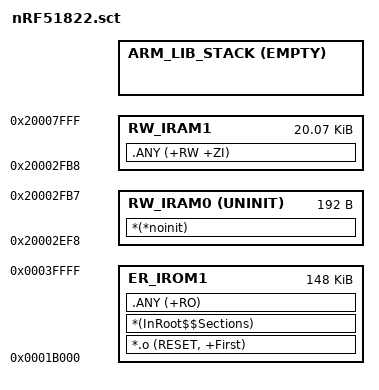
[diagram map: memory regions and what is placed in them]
#! armcc -E

;WITHOUT SOFTDEVICE:
;LR_IROM1 0x00000000 0x00040000  {
;  ER_IROM1 0x00000000 0x00040000  {
;   *.o (RESET, +First)
;   *(InRoot$$Sections)
;   .ANY (+RO)
;  }
;  RW_IRAM1 0x20000000 0x00008000  {
;   .ANY (+RW +ZI)
;  }
;}
;
;WITH SOFTDEVICE:

#define Stack_Size MBED_BOOT_STACK_SIZE

LR_IROM1 0x1B000 0x0025000  {
  ER_IROM1 0x1B000 0x0025000  {
   *.o (RESET, +First)
   *(InRoot$$Sections)
   .ANY (+RO)
  }
  RW_IRAM0 0x20002ef8 UNINIT 0x000000c0  { ;no init section
        *(*noinit)
  }
  RW_IRAM1 0x20002FB8 0x00005048  {
   .ANY (+RW +ZI)
  }
  ARM_LIB_STACK 0x20002FB8+0x00005048 EMPTY -Stack_Size { ; Stack region growing down
  }
}
